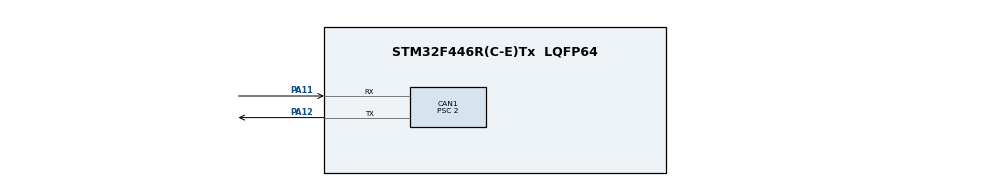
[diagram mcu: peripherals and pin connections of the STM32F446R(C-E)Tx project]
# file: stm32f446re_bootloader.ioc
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CAN1.ABOM=ENABLE
CAN1.AWUM=ENABLE
CAN1.BS1=CAN_BS1_13TQ
CAN1.BS2=CAN_BS2_2TQ
CAN1.CalculateBaudRate=500000
CAN1.CalculateTimeBit=2000
CAN1.CalculateTimeQuantum=125.0
CAN1.Prescaler=2
FREERTOS.Tasks01=defaultTask,24,128,StartDefaultTask,Default,NULL,Dynamic,NULL,NULL
Mcu.Family=STM32F4
Mcu.Name=STM32F446R(C-E)Tx
Mcu.Package=LQFP64
NVIC.PriorityGroup=NVIC_PRIORITYGROUP_4
PA11.Mode=CAN_Activate
PA11.Signal=CAN1_RX
PA12.Mode=CAN_Activate
PA12.Signal=CAN1_TX
PC14-OSC32_IN.Mode=LSE-External-Oscillator
PC14-OSC32_IN.Signal=RCC_OSC32_IN
PC15-OSC32_OUT.Mode=LSE-External-Oscillator
PC15-OSC32_OUT.Signal=RCC_OSC32_OUT
PH0-OSC_IN.Mode=HSE-External-Oscillator
PH0-OSC_IN.Signal=RCC_OSC_IN
PH1-OSC_OUT.Mode=HSE-External-Oscillator
PH1-OSC_OUT.Signal=RCC_OSC_OUT
ProjectManager.HeapSize=0x200
ProjectManager.StackSize=0x400
ProjectManager.TargetToolchain=Makefile
RCC.CortexFreq_Value=16000000
RCC.USBFreq_Value=96000000
RCC.VCOOutputFreq_Value=192000000
VP_FREERTOS_VS_CMSIS_V2.Mode=CMSIS_V2
board=custom

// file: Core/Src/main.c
/* USER CODE BEGIN Header */
/**
  ******************************************************************************
  * @file           : main.c
  * @brief          : Main program body
  ******************************************************************************
  * @attention
  *
  * Copyright (c) 2024 STMicroelectronics.
  * All rights reserved.
  *
  * This software is licensed under terms that can be found in the LICENSE file
  * in the root directory of this software component.
  * If no LICENSE file comes with this software, it is provided AS-IS.
  *
  ******************************************************************************
  */
/* USER CODE END Header */
#include "main.h"
#include "cmsis_os.h"
#include "can.h"
#include "gpio.h"

/* USER CODE BEGIN Includes */
#include "app_openbootloader.h"
#include "flash_interface.h"
#include "interfaces_conf.h"
#include "platform.h"
#include "semphr.h"
#include "util.h"

/* USER CODE END Includes */

/* USER CODE BEGIN PV */
SemaphoreHandle_t open_bootloader_running;
/* USER CODE END PV */

void SystemClock_Config(void);
void MX_FREERTOS_Init(void);

/* USER CODE BEGIN 0 */

/**
* @brief  Function implementing the mainTask thread.
* @param  argument: Not used
* @retval None
*/
void mainTask(void *argument)
{
  for (;;)
  {
    if (!xSemaphoreTake(open_bootloader_running, pdMS_TO_TICKS(1000)))
    {
      OPENBL_FLASH_JumpToAddress((uint32_t)FLASH_START_ADDRESS);
    }
  }
}

/**
* @brief  Function implementing the stOpenBootTask thread.
* @param  argument: Not used
* @retval None
*/
void stOpenBootTask(void *argument)
{
  OpenBootloader_Init();
  for (;;)
  {
    OpenBootloader_ProtocolDetection();
  }
}

/**
  * @brief  The application entry point.
  * @retval int
  */
int main(void)
{
  HAL_Init();
  SystemClock_Config();

  MX_GPIO_Init();
  MX_CAN1_Init();

  /* Create starting tasks for FreeRTOS and bootloader */
  open_bootloader_running = xSemaphoreCreateBinary();

  xTaskCreate(mainTask, "mainTask", 256, NULL, PRIORITY_MEDIUM, NULL);

  xTaskCreate(stOpenBootTask, "stOpenBootTask", 256, NULL, PRIORITY_MEDIUM, NULL);

  /* Start scheduler */
  vTaskStartScheduler();

  while (1)
  {
    /* We should never get here as control is now taken by the scheduler */
  }
}
/* USER CODE END 0 */

void SystemClock_Config(void)
{
  RCC_OscInitTypeDef RCC_OscInitStruct = {0};
  RCC_ClkInitTypeDef RCC_ClkInitStruct = {0};

  /** Configure the main internal regulator output voltage
  */
  __HAL_RCC_PWR_CLK_ENABLE();
  __HAL_PWR_VOLTAGESCALING_CONFIG(PWR_REGULATOR_VOLTAGE_SCALE3);

  /** Initializes the RCC Oscillators according to the specified parameters
  * in the RCC_OscInitTypeDef structure.
  */
  RCC_OscInitStruct.OscillatorType = RCC_OSCILLATORTYPE_HSI;
  RCC_OscInitStruct.HSIState = RCC_HSI_ON;
  RCC_OscInitStruct.HSICalibrationValue = RCC_HSICALIBRATION_DEFAULT;
  RCC_OscInitStruct.PLL.PLLState = RCC_PLL_NONE;
  if (HAL_RCC_OscConfig(&RCC_OscInitStruct) != HAL_OK)
  {
    Error_Handler();
  }

  /** Initializes the CPU, AHB and APB buses clocks
  */
  RCC_ClkInitStruct.ClockType = RCC_CLOCKTYPE_HCLK|RCC_CLOCKTYPE_SYSCLK
                              |RCC_CLOCKTYPE_PCLK1|RCC_CLOCKTYPE_PCLK2;
  RCC_ClkInitStruct.SYSCLKSource = RCC_SYSCLKSOURCE_HSI;
  RCC_ClkInitStruct.AHBCLKDivider = RCC_SYSCLK_DIV1;
  RCC_ClkInitStruct.APB1CLKDivider = RCC_HCLK_DIV1;
  RCC_ClkInitStruct.APB2CLKDivider = RCC_HCLK_DIV1;

  if (HAL_RCC_ClockConfig(&RCC_ClkInitStruct, FLASH_LATENCY_0) != HAL_OK)
  {
    Error_Handler();
  }
}

void Error_Handler(void)
{
  __disable_irq();
  while (1)
  {
  }
}

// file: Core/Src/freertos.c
/* USER CODE BEGIN Header */
/**
  ******************************************************************************
  * File Name          : freertos.c
  * Description        : Code for freertos applications
  ******************************************************************************
  * @attention
  *
  * Copyright (c) 2025 STMicroelectronics.
  * All rights reserved.
  *
  * This software is licensed under terms that can be found in the LICENSE file
  * in the root directory of this software component.
  * If no LICENSE file comes with this software, it is provided AS-IS.
  *
  ******************************************************************************
  */
/* USER CODE END Header */

#include "FreeRTOS.h"
#include "task.h"
#include "main.h"
#include "cmsis_os.h"

/* Definitions for defaultTask */
osThreadId_t defaultTaskHandle;
const osThreadAttr_t defaultTask_attributes = {
  .name = "defaultTask",
  .stack_size = 128 * 4,
  .priority = (osPriority_t) osPriorityNormal,
};

void StartDefaultTask(void *argument);

void MX_FREERTOS_Init(void); /* (MISRA C 2004 rule 8.1) */

void MX_FREERTOS_Init(void) {

  /* Create the thread(s) */
  /* creation of defaultTask */
  defaultTaskHandle = osThreadNew(StartDefaultTask, NULL, &defaultTask_attributes);

}

void StartDefaultTask(void *argument)
{
  for (;;)
  {
    osDelay(1);
  }
}
